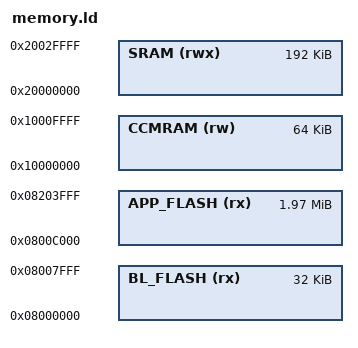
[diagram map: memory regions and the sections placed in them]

MEMORY
{
    BL_FLASH  (rx)  : ORIGIN = 0x08000000, LENGTH = 32K
    APP_FLASH (rx)  : ORIGIN = 0x0800C000, LENGTH = 2016K
    SRAM      (rwx) : ORIGIN = 0x20000000, LENGTH = 192K
    CCMRAM    (rw)  : ORIGIN = 0x10000000, LENGTH = 64K
}
